VERSION ""

NS_ :

BS_:
BU_: PPEI_Engine PPEI_Chassis PPEI_Transmission
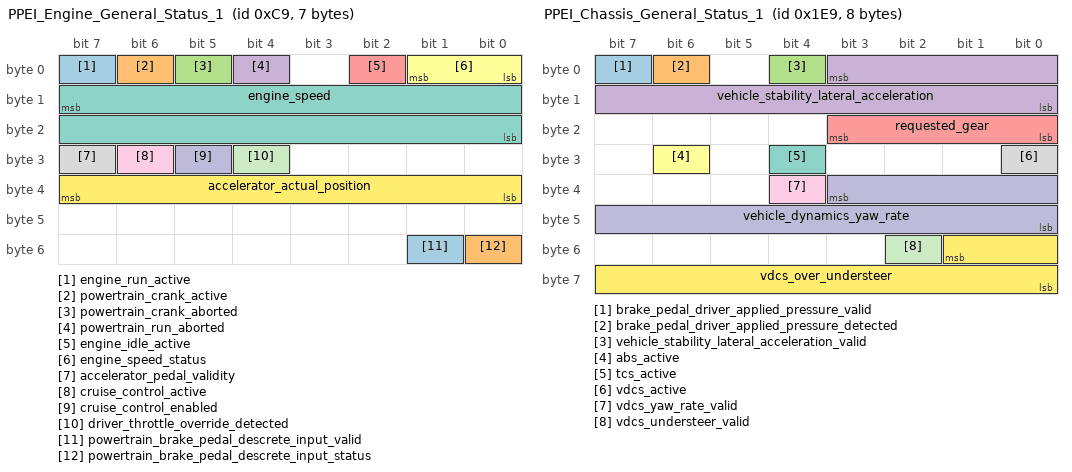
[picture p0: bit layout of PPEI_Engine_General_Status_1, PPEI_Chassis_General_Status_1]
BO_ 201 PPEI_Engine_General_Status_1: 7 PPEI_Engine
   SG_ engine_run_active : 7|1@1+ (1,0) [0|1] "" Vector__XXX
   SG_ powertrain_crank_active : 6|1@1+ (1,0) [0|1] "" Vector__XXX
   SG_ powertrain_crank_aborted : 5|1@1+ (1,0) [0|1] "" Vector__XXX
   SG_ powertrain_run_aborted : 4|1@1+ (1,0) [0|1] "" Vector__XXX
   SG_ engine_idle_active : 2|1@1+ (1,0) [0|1] "" Vector__XXX
   SG_ engine_speed_status : 0|2@1+ (1,0) [0|0] "" Vector__XXX
   SG_ engine_speed : 15|16@0+ (0.25,0) [0|16383.8] "RPM" Vector__XXX
   SG_ accelerator_pedal_validity : 31|1@1+ (1,0) [0|1] "" Vector__XXX
   SG_ cruise_control_active : 30|1@1+ (1,0) [0|1] "" Vector__XXX
   SG_ cruise_control_enabled : 29|1@1+ (1,0) [0|1] "" Vector__XXX
   SG_ driver_throttle_override_detected : 28|1@1+ (1,0) [0|1] "" Vector__XXX
   SG_ accelerator_actual_position : 32|8@1+ (0.393156,0) [0|100] "%" Vector__XXX
   SG_ powertrain_brake_pedal_descrete_input_valid : 49|1@1+ (1,0) [0|1] "" Vector__XXX
   SG_ powertrain_brake_pedal_descrete_input_status : 48|1@1+ (1,0) [0|1] "" Vector__XXX

BO_ 241 PPEI_Engine_General_Status_1a: 4 PPEI_Engine
   SG_ moderate_brake_achieved : 6|1@1+ (1,0) [0|1] "" Vector__XXX
   SG_ platform_brake_position : 8|8@1+ (0.393156,0) [0|100] "%" Vector__XXX

BO_ 451 PPEI_Engine_Torque_Status_2: 5 PPEI_Engine
   SG_ engine_torque_actual_ex : 3|12@0+ (0.5,-848) [-848|1199.5] "Nm" Vector__XXX
   SG_ engine_torque_driver_req_ex : 19|12@0+ (0.5,-848) [-848|1199.5] "Nm" Vector__XXX

BO_ 489 PPEI_Chassis_General_Status_1: 8 PPEI_Chassis
   SG_ brake_pedal_driver_applied_pressure_valid : 7|1@1+ (1,0) [0|1] "" Vector__XXX
   SG_ brake_pedal_driver_applied_pressure_detected : 6|1@1+ (1,0) [0|1] "" Vector__XXX
   SG_ vehicle_stability_lateral_acceleration_valid : 4|1@1+ (1,0) [0|1] "" Vector__XXX
   SG_ vehicle_stability_lateral_acceleration : 3|12@0- (0.015625,0) [-32|31.9844] "m/s^2" Vector__XXX
   SG_ requested_gear : 16|4@1+ (1,0) [0|0] "" Vector__XXX
   SG_ abs_active : 30|1@1+ (1,0) [0|1] "" Vector__XXX
   SG_ tcs_active : 28|1@1+ (1,0) [0|1] "" Vector__XXX
   SG_ vdcs_active : 24|1@1+ (1,0) [0|1] "" Vector__XXX
   SG_ vdcs_yaw_rate_valid : 36|1@1+ (1,0) [0|1] "" Vector__XXX
   SG_ vehicle_dynamics_yaw_rate : 35|12@0- (0.0625,-128) [-128|128] "Degrees/sec" Vector__XXX
   SG_ vdcs_understeer_valid : 50|1@1+ (1,0) [0|1] "" Vector__XXX
   SG_ vdcs_over_understeer : 49|10@0- (0.5,0) [-256|256] "%" Vector__XXX

BO_ 485 PPEI_Steering_Wheel_Angle: 8 PPEI_Chassis
   SG_ steering_wheel_angle : 15|16@0- (0.0625,0) [-2048|2048] "Degrees" Vector__XXX

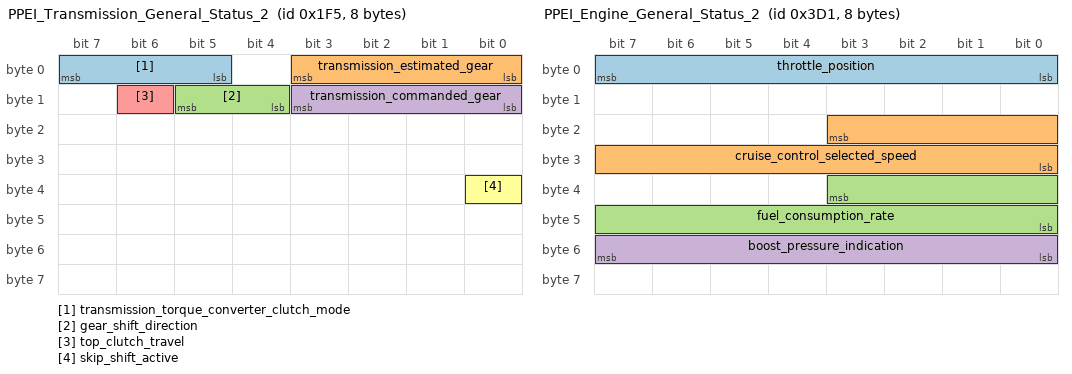
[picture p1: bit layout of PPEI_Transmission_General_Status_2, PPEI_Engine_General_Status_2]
BO_ 501 PPEI_Transmission_General_Status_2: 8 PPEI_Transmission
   SG_ transmission_torque_converter_clutch_mode : 5|3@1+ (1,0) [0|0] "" Vector__XXX
   SG_ transmission_estimated_gear : 0|4@1+ (1,0) [0|0] "Gear_Number" Vector__XXX
   SG_ gear_shift_direction : 12|2@1- (1,0) [0|0] "Direction" Vector__XXX
   SG_ transmission_commanded_gear : 8|4@1+ (1,0) [0|0] "Gear" Vector__XXX
   SG_ top_clutch_travel : 14|1@1+ (1,0) [0|1] "" Vector__XXX
   SG_ skip_shift_active : 32|1@1+ (1,0) [0|1] "" Vector__XXX

BO_ 977 PPEI_Engine_General_Status_2: 8 PPEI_Engine
   SG_ throttle_position : 0|8@1+ (0.393156,0) [0|100] "%" Vector__XXX
   SG_ cruise_control_selected_speed : 19|12@0+ (0.0625,0) [0|256] "kph" Vector__XXX
   SG_ fuel_consumption_rate : 35|12@0+ (0.025,0) [0|102.375] "l/h" Vector__XXX
   SG_ boost_pressure_indication : 48|8@1+ (0.393156,0) [0|100] "%" Vector__XXX

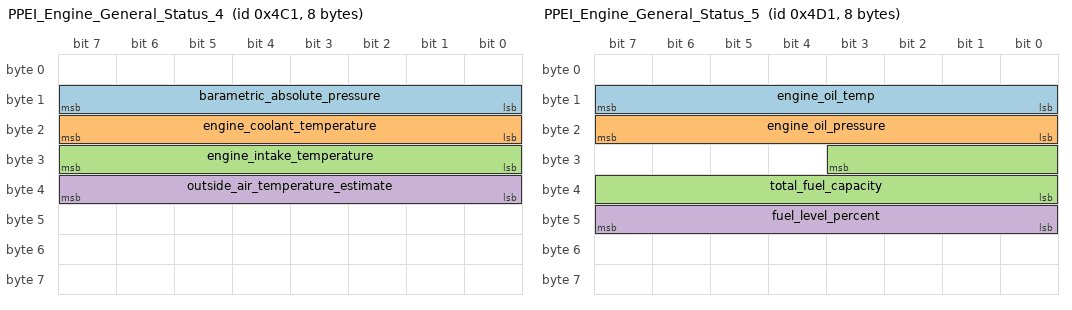
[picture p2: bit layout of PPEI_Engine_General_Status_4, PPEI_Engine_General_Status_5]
BO_ 1217 PPEI_Engine_General_Status_4: 8 PPEI_Engine
   SG_ barametric_absolute_pressure : 8|8@1+ (0.5,0) [0|127.5] "kpa" Vector__XXX
   SG_ engine_coolant_temperature : 16|8@1+ (1,-40) [-40|215] "C" Vector__XXX
   SG_ engine_intake_temperature : 24|8@1+ (1,-40) [-40|215] "C" Vector__XXX
   SG_ outside_air_temperature_estimate : 32|8@1+ (0.5,-40) [-40|87.5] "C" Vector__XXX

BO_ 1225 PPEI_Transmission_General_Status_3: 8 PPEI_Transmission
   SG_ trans_oil_temp : 8|8@1+ (1,-40) [-40|215] "C" Vector__XXX

BO_ 1233 PPEI_Engine_General_Status_5: 8 PPEI_Engine
   SG_ engine_oil_temp : 8|8@1+ (1,-40) [-40|215] "C" Vector__XXX
   SG_ engine_oil_pressure : 16|8@1+ (4,0) [0|1020] "kPa" Vector__XXX
   SG_ total_fuel_capacity : 27|12@0+ (0.125,0) [0|512] "L" Vector__XXX
   SG_ fuel_level_percent : 40|8@1+ (0.39215,0) [0|100] "%" Vector__XXX

BO_ 1001 PPEI_Vehicle_Speed_and_Distance: 8 PPEI_Engine
   SG_ speed_average_driven : 6|15@0+ (0.015625,0) [0|512] "kph" Vector__XXX
   SG_ speed_average_non_driven : 38|15@0+ (0.015625,0) [0|512] "kph" Vector__XXX

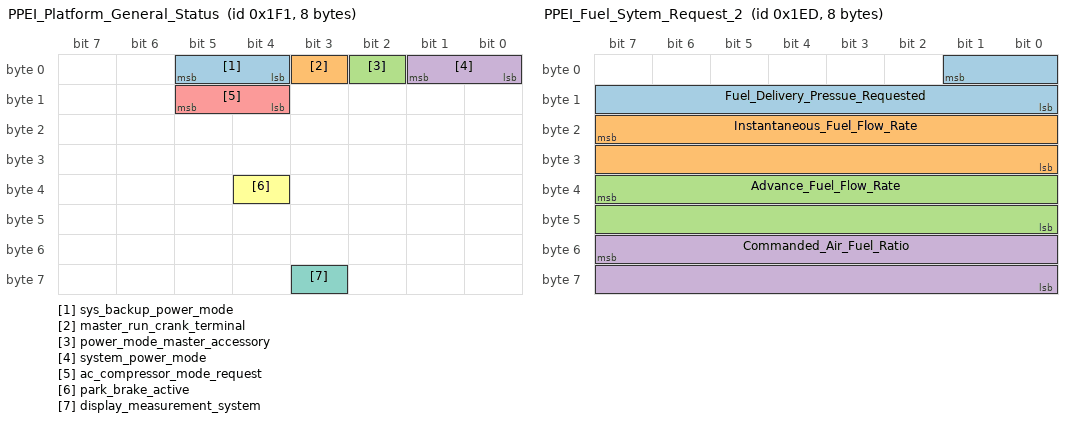
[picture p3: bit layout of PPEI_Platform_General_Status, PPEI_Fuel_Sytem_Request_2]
BO_ 497 PPEI_Platform_General_Status: 8 PPEI_Chassis
   SG_ sys_backup_power_mode : 4|2@1+ (1,0) [0|0] "" Vector__XXX
   SG_ master_run_crank_terminal : 3|1@1+ (1,0) [0|1] "" Vector__XXX
   SG_ power_mode_master_accessory : 2|1@1+ (1,0) [0|1] "" Vector__XXX
   SG_ system_power_mode : 1|2@0+ (1,0) [0|1] "" Vector__XXX
   SG_ ac_compressor_mode_request : 12|2@1+ (1,0) [0|1] "" Vector__XXX
   SG_ park_brake_active : 36|1@1+ (1,0) [0|1] "" Vector__XXX
   SG_ display_measurement_system : 59|1@1+ (1,0) [0|1] "" Vector__XXX

BO_ 495 PPEI_Fuel_System_Request_2: 8 PPEI_Engine
   SG_ mass_airflow : 16|16@1+ (0.01,0) [0|656] "gram/s" Vector__XXX

BO_ 491 PPEI_Fuel_System_Status: 2 PPEI_Engine
   SG_ fuel_system_estimated_pressure : 1|10@0+ (1,0) [0|1023] "kPa" Vector__XXX

BO_ 249 PPEI_Transmission_General_Status_1: 8 PPEI_Transmission
   SG_ Estimated_Torque_Ratio : 6|15@0- (0.0039,0) [-64|63.99] "Ratio" Vector__XXX
   SG_ Output_Shaft_Angular_Velocity : 31|16@0+ (0.25,0) [0|16383.8] "rpm" Vector__XXX

BO_ 455 PPEI_Chassis_Engine_Torque_Request_1: 7 PPEI_Chassis
   SG_ Torque_Intervention_Type : 4|2@1+ (1,0) [0|0] "" Vector__XXX
   SG_ Torque_Request_Value : 3|12@0+ (0.5,-848) [-848|1199.5] "Nm" Vector__XXX

BO_ 493 PPEI_Fuel_Sytem_Request_2: 8 PPEI_Engine
   SG_ Fuel_Delivery_Pressue_Requested : 1|10@0+ (1,0) [0|1023] "kPa" Vector__XXX
   SG_ Instantaneous_Fuel_Flow_Rate : 23|16@0+ (0.000976563,0) [0|84] "g/s" Vector__XXX
   SG_ Advance_Fuel_Flow_Rate : 39|16@0+ (0.000976563,0) [0|84] "g/s" Vector__XXX
   SG_ Commanded_Air_Fuel_Ratio : 55|16@0+ (0.000488,0) [0|32] "" Vector__XXX

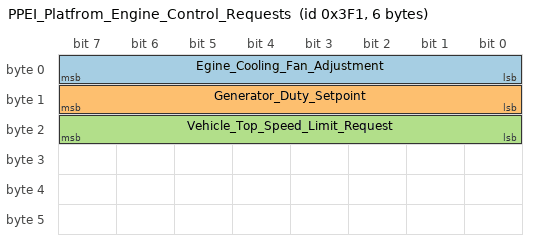
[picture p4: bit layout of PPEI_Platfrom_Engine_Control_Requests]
BO_ 1009 PPEI_Platfrom_Engine_Control_Requests: 6 PPEI_Engine
   SG_ Egine_Cooling_Fan_Adjustment : 7|8@0- (0.7812,0) [-100|100] "%" Vector__XXX
   SG_ Generator_Duty_Setpoint : 15|8@0+ (0.3906,0) [-100|100] "%" Vector__XXX
   SG_ Vehicle_Top_Speed_Limit_Request : 23|8@0+ (2,0) [0|512] "kph" Vector__XXX

BO_ 1017 PPEI_Engine_General_Status_3: 8 PPEI_Engine
   SG_ Fan_Speed : 47|8@0+ (0.3906,0) [0|100] "%" Vector__XXX
   SG_ Oil_Life_Remaining : 55|8@0+ (0.3906,0) [0|100] "%" Vector__XXX

BO_ 1019 PPEI_Engine_Fuel_Status: 2 PPEI_Engine
   SG_ Engine_Fuel_Control_State : 1|2@0+ (1,0) [0|0] "" Vector__XXX
   SG_ Fuel_Alcohol_Composition : 15|8@0+ (0.3906,0) [0|100] "%" Vector__XXX

BA_DEF_ BO_ "GenMsgBackgroundColor" STRING ;
BA_DEF_ BO_ "GenMsgForegroundColor" STRING ;
BA_ "GenMsgForegroundColor" BO_ 489 "#00aaff";
BA_ "GenMsgForegroundColor" BO_ 485 "#00aaff";
BA_ "GenMsgForegroundColor" BO_ 501 "#ff007f";
BA_ "GenMsgForegroundColor" BO_ 1225 "#ff007f";
BA_ "GenMsgForegroundColor" BO_ 497 "#00aaff";
BA_ "GenMsgForegroundColor" BO_ 249 "#ff007f";
BA_ "GenMsgForegroundColor" BO_ 455 "#00aaff";
BA_DEF_DEF_ "GenMsgBackgroundColor" "#ffffff";
BA_DEF_DEF_ "GenMsgForegroundColor" "#000000";
CM_ SG_ 489 vehicle_dynamics_yaw_rate "Yaw_Rate";
VAL_ 201 engine_speed_status 0 "Normal_Operation" 1 "Degraded_Operation" 2 "Undefined" 3 "Invalid";
VAL_ 489 requested_gear 0 "No_Action" 1 "First_Gear" 2 "Second_Gear" 3 "Third_Gear" 4 "Forth_Gear" 5 "Fifth_Gear" 6 "Sixth_Gear" 7 "Seventh_Gear" 8 "Eigth_Gear";
VAL_ 501 transmission_torque_converter_clutch_mode 0 "Unlocked" 1 "Transition" 2 "Controlled_Slip" 3 "Locked" 7 "Not_Supported";
VAL_ 501 transmission_estimated_gear 15 "Park" 14 "Reverse" 0 "No Description";
VAL_ 497 sys_backup_power_mode 0 "Off" 1 "Accessory" 2 "Run" 3 "Crank_Request";
VAL_ 497 system_power_mode 0 "Off" 1 "Accessory" 2 "Run" 3 "Crank_Request";
VAL_ 455 Torque_Intervention_Type 0 "No_Intervention" 1 "Reduce_Torque" 2 "Increase_Torque";
VAL_ 1019 Engine_Fuel_Control_State 0 "Open_Loop" 1 "Non-Stoichometric_Closed_Loop" 2 "Closed_Loop";
